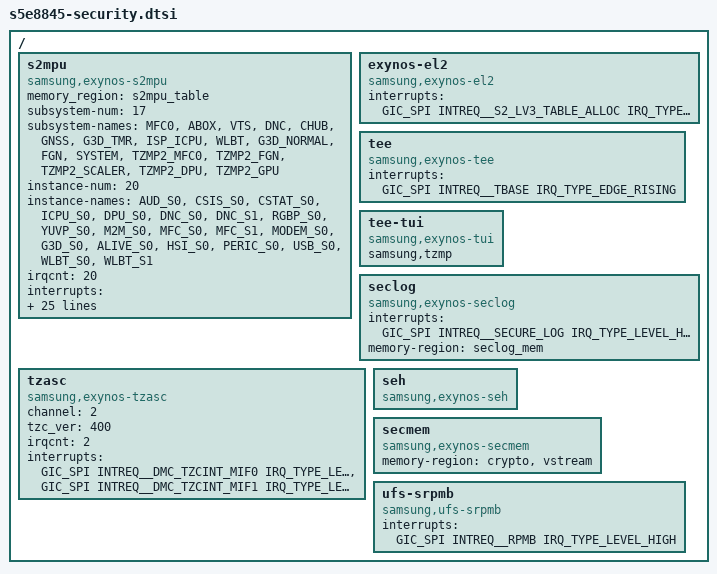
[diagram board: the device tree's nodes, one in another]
/*
 * SAMSUNG S5E8845 SoC security device tree source
 *
 * Copyright (c) 2022 Samsung Electronics Co., Ltd.
 *              http://www.samsung.com
 *
 * SAMSUNG S5E8845 SoC security device nodes are listed in this file.
 * EXYNOS based board files can include this file and provide
 * values for board specfic bindings.
 *
 * This program is free software; you can redistribute it and/or modify
 * it under the terms of the GNU General Public License version 2 as
 * published by the Free Software Foundation.
 */

#include <dt-bindings/interrupt-controller/s5e8845.h>

/ {
	s2mpu {
		compatible = "samsung,exynos-s2mpu";
		memory_region = <&s2mpu_table>;
		subsystem-num = <17>;
		subsystem-names = "MFC0",
				  "ABOX",
				  "VTS",
				  "DNC",
				  "CHUB",
				  "GNSS",
				  "G3D_TMR",
				  "ISP_ICPU",
				  "WLBT",
				  "G3D_NORMAL",
				  "FGN",
				  "SYSTEM",
				  "TZMP2_MFC0",
				  "TZMP2_FGN",
				  "TZMP2_SCALER",
				  "TZMP2_DPU",
				  "TZMP2_GPU";
		instance-num = <20>;
		instance-names = "AUD_S0",
				 "CSIS_S0",
				 "CSTAT_S0",
				 "ICPU_S0",
				 "DPU_S0",
				 "DNC_S0",
				 "DNC_S1",
				 "RGBP_S0",
				 "YUVP_S0",
				 "M2M_S0",
				 "MFC_S0",
				 "MFC_S1",
				 "MODEM_S0",
				 "G3D_S0",
				 "ALIVE_S0",
				 "HSI_S0",
				 "PERIC_S0",
				 "USB_S0",
				 "WLBT_S0",
				 "WLBT_S1";
		irqcnt = <20>;
		interrupts = <GIC_SPI INTREQ__SYSMMU_ABOX_S2_NS IRQ_TYPE_LEVEL_HIGH>,
			     <GIC_SPI INTREQ__SYSMMU_S0_CSIS_S2_NS IRQ_TYPE_LEVEL_HIGH>,
			     <GIC_SPI INTREQ__SYSMMU_S0_CSTAT_S2_NS IRQ_TYPE_LEVEL_HIGH>,
			     <GIC_SPI INTREQ__SYSMMU_S0_ICPU_S2_NS IRQ_TYPE_LEVEL_HIGH>,
			     <GIC_SPI INTREQ__SYSMMU_DPU_S0_STAGE2_NONSEC IRQ_TYPE_LEVEL_HIGH>,
			     <GIC_SPI INTREQ__FROM_DNC_SYSMMU_DNC_S0_O_STAGE2_NONSEC IRQ_TYPE_LEVEL_HIGH>,
			     <GIC_SPI INTREQ__FROM_DNC_SYSMMU_DNC_S1_O_STAGE2_NONSEC IRQ_TYPE_LEVEL_HIGH>,
			     <GIC_SPI INTREQ__SYSMMU_S0_RGBP_S2_NS IRQ_TYPE_LEVEL_HIGH>,
			     <GIC_SPI INTREQ__SYSMMU_YUVP_S0_S2_NS IRQ_TYPE_LEVEL_HIGH>,
			     <GIC_SPI INTREQ__SYSMMU_S0_M2M_STAGE2_NONSEC IRQ_TYPE_LEVEL_HIGH>,
			     <GIC_SPI INTREQ__SYSMMU_MFC_S0_interrupt_s2_ns IRQ_TYPE_LEVEL_HIGH>,
			     <GIC_SPI INTREQ__SYSMMU_MFC_S1_interrupt_s2_ns IRQ_TYPE_LEVEL_HIGH>,
			     <GIC_SPI INTREQ_SYSMMU_MODEM_S2_NS IRQ_TYPE_LEVEL_HIGH>,
			     <GIC_SPI INTREQ_S2MPU_G3D_S2_NS IRQ_TYPE_LEVEL_HIGH>,
			     <GIC_SPI INTREQ__S2MPU_S0_ALIVE_O_INTERRUPT_STAGE2_NONSEC IRQ_TYPE_LEVEL_HIGH>,
			     <GIC_SPI INTREQ__S2MPU_HSI_S0_S2_NS IRQ_TYPE_LEVEL_HIGH>,
			     <GIC_SPI INTREQ__S2MPU_S0_PERIC_S2_NS IRQ_TYPE_LEVEL_HIGH>,
			     <GIC_SPI INTREQ__S2MPU_USB_S0_S2_NS IRQ_TYPE_LEVEL_HIGH>,
			     <GIC_SPI WB2AP_O_DBUS_INTERRUPT_STAGE2_NONSEC IRQ_TYPE_LEVEL_HIGH>,
			     <GIC_SPI WB2AP_O_LPBUS_INTERRUPT_STAGE2_NONSEC IRQ_TYPE_LEVEL_HIGH>;

		/* PM QoS for SSS */
		pm-qos-sss-support;
		sss-freq-domain = "INT";
		qos-sss-freq = <400000>;

		/* S2MPU version */
		s2mpu-version = <0x90>;

		/* S2MPU Revision version */
		s2mpu-revision = <0x1>;
	};

	exynos-el2 {
		compatible = "samsung,exynos-el2";
		interrupts = <GIC_SPI INTREQ__S2_LV3_TABLE_ALLOC IRQ_TYPE_LEVEL_HIGH>;
	};

	/* tbase */
	tee {
		compatible = "samsung,exynos-tee";
		interrupts = <GIC_SPI INTREQ__TBASE IRQ_TYPE_EDGE_RISING>;
	};

	tee-tui {
		compatible = "samsung,exynos-tui";
		samsung,tzmp;
	};

	/* Secure Log */
	seclog {
		compatible = "samsung,exynos-seclog";
		interrupts = <GIC_SPI INTREQ__SECURE_LOG IRQ_TYPE_LEVEL_HIGH>;
		memory-region = <&seclog_mem>;
	};

	tzasc {
		compatible = "samsung,exynos-tzasc";
		channel = <2>;
		tzc_ver = <400>;
		irqcnt = <2>;
		interrupts = <GIC_SPI INTREQ__DMC_TZCINT_MIF0 IRQ_TYPE_LEVEL_HIGH>,
			   <GIC_SPI INTREQ__DMC_TZCINT_MIF1 IRQ_TYPE_LEVEL_HIGH>;
	};

	seh {
		compatible = "samsung,exynos-seh";
	};

//	ppmpu {
//		compatible = "samsung,exynos-ppmpu";
//		channel = <4>;
//		tzc_ver = <400>;
//		irqcnt = <4>;
//		interrupts = <GIC_SPI INTREQ__DMC_PPMPINT_MIF0 IRQ_TYPE_LEVEL_HIGH>,
//			   <GIC_SPI INTREQ__DMC_PPMPINT_MIF1 IRQ_TYPE_LEVEL_HIGH>,
//			   <GIC_SPI INTREQ__DMC_PPMPINT_MIF2 IRQ_TYPE_LEVEL_HIGH>,
//			   <GIC_SPI INTREQ__DMC_PPMPINT_MIF3 IRQ_TYPE_LEVEL_HIGH>;
//	};
//
//	hdcp {
//		compatible = "samsung,exynos-hdcp";
//		interrupts = <GIC_SPI INTREQ__HDCP IRQ_TYPE_LEVEL_HIGH>;
//	};
//
	secmem {
		compatible = "samsung,exynos-secmem";
		memory-region = <&crypto>, <&vstream>;
	};

	/* Secure RPMB */
	ufs-srpmb {
		compatible = "samsung,ufs-srpmb";
		interrupts = <GIC_SPI INTREQ__RPMB IRQ_TYPE_LEVEL_HIGH>;
	};
//
//	fmp {
//		compatible = "samsung,exynos-fmp";
//	};
//
//	ssp: ssp {
//		compatible = "samsung,exynos-ssp";
//		power-domains = <&pd_strong>;
//	};
//
//	camellia_test {
//		compatible = "samsung,exynos-camellia-test";
//	};
//
//	/* CryptoManager */
//	cryptomanager {
//		compatible = "samsung,exynos-cm";
//		cryptomanager-ver="CryptoManagerV70";
//		sysreg_addr = <0x18221018>;
//		ap_addr = <0x18290000>;
//		cp_addr = <0x18280000>;
//	};
};
